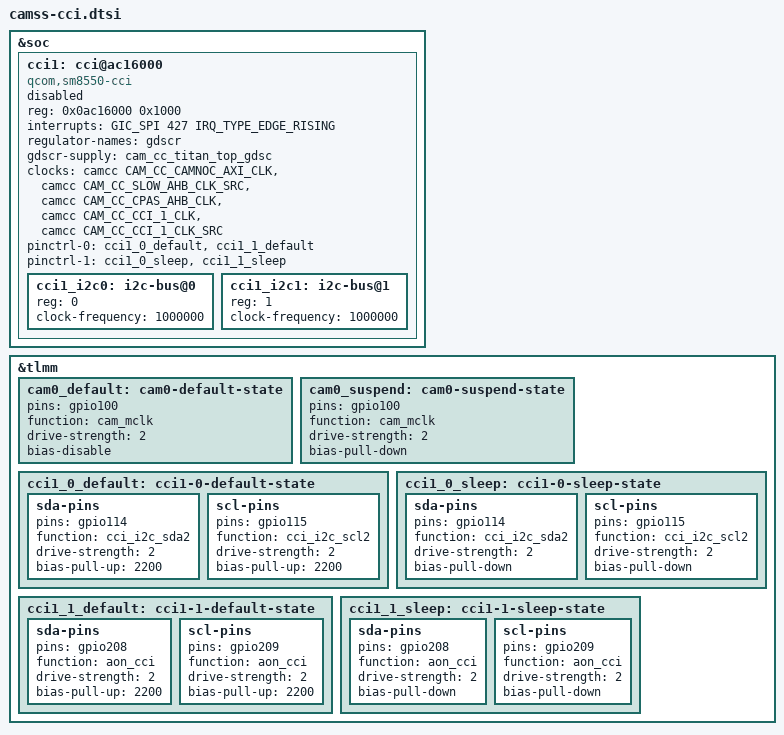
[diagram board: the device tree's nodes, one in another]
#include <dt-bindings/interrupt-controller/arm-gic.h>
#include <dt-bindings/clock/qcom,camcc-kalama.h>
#include <dt-bindings/clock/qcom,dispcc-kalama.h>
#include <dt-bindings/clock/qcom,gcc-kalama.h>
#include <dt-bindings/clock/qcom,gpucc-kalama.h>
#include <dt-bindings/clock/qcom,rpmh.h>
#include <dt-bindings/clock/qcom,tcsrcc-kalama.h>
#include <dt-bindings/clock/qcom,videocc-kalama.h>
#include <dt-bindings/regulator/qcom,rpmh-regulator-levels.h>
#include <dt-bindings/interconnect/qcom,kalama.h>
#include <dt-bindings/soc/qcom,ipcc.h>
#include <dt-bindings/soc/qcom,rpmh-rsc.h>
#include <dt-bindings/interconnect/qcom,icc.h>
#include <dt-bindings/spmi/spmi.h>
#include <dt-bindings/power/qcom-aoss-qmp.h>
#include <dt-bindings/clock/qcom,aop-qmp.h>

&soc {
	#address-cells = <1>;
	#size-cells = <1>;

	cci1: cci@ac16000 {
		compatible = "qcom,sm8550-cci", "qcom,msm8996-cci";
		#address-cells = <1>;
		#size-cells = <0>;
		status = "disabled";

		reg = <0x0ac16000 0x1000>;
		interrupts = <GIC_SPI 427 IRQ_TYPE_EDGE_RISING>;
		regulator-names = "gdscr";
		gdscr-supply = <&cam_cc_titan_top_gdsc>;

		clocks = <&camcc CAM_CC_CAMNOC_AXI_CLK>,
			 <&camcc CAM_CC_SLOW_AHB_CLK_SRC>,
			 <&camcc CAM_CC_CPAS_AHB_CLK>,
			 <&camcc CAM_CC_CCI_1_CLK>,
			 <&camcc CAM_CC_CCI_1_CLK_SRC>;
		clock-names = "camnoc_axi",
			      "slow_ahb_src",
			      "cpas_ahb",
			      "cci",
			      "cci_src";

		pinctrl-0 = <&cci1_0_default &cci1_1_default>;
		pinctrl-1 = <&cci1_0_sleep &cci1_1_sleep>;
		pinctrl-names = "default", "sleep";

		cci1_i2c0: i2c-bus@0 {
			reg = <0>;
			clock-frequency = <1000000>;
			#address-cells = <1>;
			#size-cells = <0>;
		};

		cci1_i2c1: i2c-bus@1 {
			reg = <1>;
			clock-frequency = <1000000>;
			#address-cells = <1>;
			#size-cells = <0>;
		};
	};
};

&tlmm {
	cam0_default: cam0-default-state {
		pins = "gpio100";
		function = "cam_mclk";
		drive-strength = <2>;
		bias-disable;
	};

	cam0_suspend: cam0-suspend-state {
		pins = "gpio100";
		function = "cam_mclk";
		drive-strength = <2>;
		bias-pull-down;
	};

	cci1_0_default: cci1-0-default-state {
		sda-pins {
			pins = "gpio114";
			function = "cci_i2c_sda2";
			drive-strength = <2>;
			bias-pull-up = <2200>;
		};

		scl-pins {
			pins = "gpio115";
			function = "cci_i2c_scl2";
			drive-strength = <2>;
			bias-pull-up = <2200>;
		};
	};

	cci1_0_sleep: cci1-0-sleep-state {
		sda-pins {
			pins = "gpio114";
			function = "cci_i2c_sda2";
			drive-strength = <2>;
			bias-pull-down;
		};

		scl-pins {
			pins = "gpio115";
			function = "cci_i2c_scl2";
			drive-strength = <2>;
			bias-pull-down;
		};
	};

	cci1_1_default: cci1-1-default-state {
		sda-pins {
			pins = "gpio208";
			function = "aon_cci";
			drive-strength = <2>;
			bias-pull-up = <2200>;
		};

		scl-pins {
			pins = "gpio209";
			function = "aon_cci";
			drive-strength = <2>;
			bias-pull-up = <2200>;
		};
	};

	cci1_1_sleep: cci1-1-sleep-state {
		sda-pins {
			pins = "gpio208";
			function = "aon_cci";
			drive-strength = <2>;
			bias-pull-down;
		};

		scl-pins {
			pins = "gpio209";
			function = "aon_cci";
			drive-strength = <2>;
			bias-pull-down;
		};
	};
};
